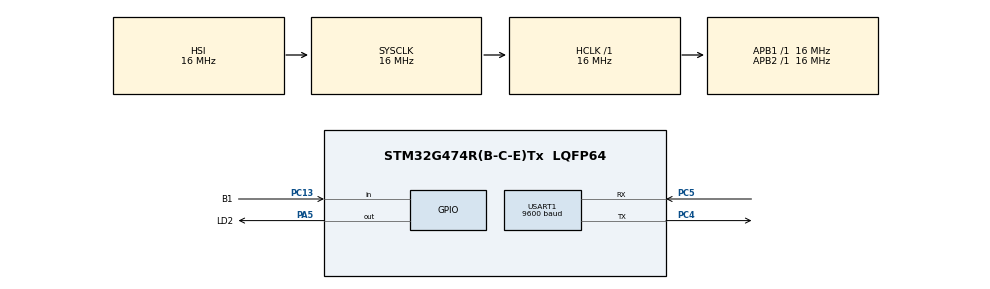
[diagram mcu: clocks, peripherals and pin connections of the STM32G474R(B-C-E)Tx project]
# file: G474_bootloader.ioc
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Mcu.Family=STM32G4
Mcu.Name=STM32G474R(B-C-E)Tx
Mcu.Package=LQFP64
NVIC.PriorityGroup=NVIC_PRIORITYGROUP_4
PA5.GPIO_Label=LD2
PA5.Signal=GPIO_Output
PC13.GPIO_Label=B1
PC13.Signal=GPIO_Input
PC4.Mode=Asynchronous
PC4.Signal=USART1_TX
PC5.Mode=Asynchronous
PC5.Signal=USART1_RX
ProjectManager.HeapSize=0x200
ProjectManager.StackSize=0x400
ProjectManager.TargetToolchain=STM32CubeIDE
RCC.ADC12Freq_Value=16000000
RCC.ADC345Freq_Value=16000000
RCC.AHBFreq_Value=16000000
RCC.APB1Freq_Value=16000000
RCC.APB1TimFreq_Value=16000000
RCC.APB2Freq_Value=16000000
RCC.APB2TimFreq_Value=16000000
RCC.CortexFreq_Value=16000000
RCC.EXTERNAL_CLOCK_VALUE=12288000
RCC.HCLKFreq_Value=16000000
RCC.HSE_VALUE=24000000
RCC.HSI48_VALUE=48000000
RCC.HSI_VALUE=16000000
RCC.LSE_VALUE=32768
RCC.PLLM=RCC_PLLM_DIV4
RCC.PLLN=85
RCC.RTCClockSelection=RCC_RTCCLKSOURCE_LSE
RCC.SYSCLKFreq_VALUE=16000000
RCC.USBFreq_Value=170000000
RCC.VCOOutputFreq_Value=340000000
USART1.BaudRate=9600
USART1.VirtualMode-Asynchronous=VM_ASYNC
VP_SYS_VS_DBSignals.Mode=DisableDeadBatterySignals
board=NUCLEO-G474RE

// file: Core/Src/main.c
/* USER CODE BEGIN Header */
/**
 ******************************************************************************
 * @file           : main.c
 * @brief          : Main program body
 ******************************************************************************
 * @attention
 *
 * Copyright (c) 2023 STMicroelectronics.
 * All rights reserved.
 *
 * This software is licensed under terms that can be found in the LICENSE file
 * in the root directory of this software component.
 * If no LICENSE file comes with this software, it is provided AS-IS.
 *
 ******************************************************************************
 */
/* USER CODE END Header */
#include "main.h"
#include "gpio.h"
#include "usart.h"

/* USER CODE BEGIN Includes */
#include "bootloader.h"
/* USER CODE END Includes */

void SystemClock_Config(void);

int main(void) {

	/* MCU Configuration--------------------------------------------------------*/

	/* Reset of all peripherals, Initializes the Flash interface and the Systick. */
	HAL_Init();

	/* Configure the system clock */
//	SystemClock_Config();

	/* Initialize all configured peripherals */
	MX_GPIO_Init();

	/* USER CODE BEGIN 2 */
	if (HAL_GPIO_ReadPin(B1_GPIO_Port, B1_Pin) == 1) {
		MX_USART1_UART_Init();
		vStartBootloader();
	} else {
		if (*((uint32_t *)APP_START_ADDRESS) == SRAM_END) {
			vJumpToApp();
		}
	}
	/* USER CODE END 2 */
	/* Infinite loop */
	while (1) {

	}
}

void SystemClock_Config(void) {
	RCC_OscInitTypeDef RCC_OscInitStruct = {0};
	RCC_ClkInitTypeDef RCC_ClkInitStruct = {0};

	/** Configure the main internal regulator output voltage
	 */
	HAL_PWREx_ControlVoltageScaling(PWR_REGULATOR_VOLTAGE_SCALE1);

	/** Initializes the RCC Oscillators according to the specified parameters
	 * in the RCC_OscInitTypeDef structure.
	 */
	RCC_OscInitStruct.OscillatorType = RCC_OSCILLATORTYPE_HSI;
	RCC_OscInitStruct.HSIState = RCC_HSI_ON;
	RCC_OscInitStruct.HSICalibrationValue = RCC_HSICALIBRATION_DEFAULT;
	RCC_OscInitStruct.PLL.PLLState = RCC_PLL_NONE;
	if (HAL_RCC_OscConfig(&RCC_OscInitStruct) != HAL_OK) {
		Error_Handler();
	}

	/** Initializes the CPU, AHB and APB buses clocks
	 */
	RCC_ClkInitStruct.ClockType = RCC_CLOCKTYPE_HCLK | RCC_CLOCKTYPE_SYSCLK | RCC_CLOCKTYPE_PCLK1 | RCC_CLOCKTYPE_PCLK2;
	RCC_ClkInitStruct.SYSCLKSource = RCC_SYSCLKSOURCE_HSI;
	RCC_ClkInitStruct.AHBCLKDivider = RCC_SYSCLK_DIV1;
	RCC_ClkInitStruct.APB1CLKDivider = RCC_HCLK_DIV1;
	RCC_ClkInitStruct.APB2CLKDivider = RCC_HCLK_DIV1;

	if (HAL_RCC_ClockConfig(&RCC_ClkInitStruct, FLASH_LATENCY_0) != HAL_OK) {
		Error_Handler();
	}
}

void Error_Handler(void) {
	__disable_irq();
	while (1) {
	}
}
